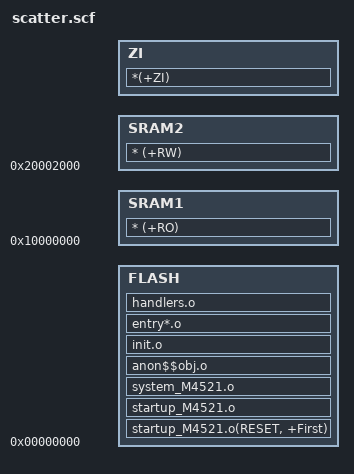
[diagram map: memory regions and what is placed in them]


FLASH 0x00000000
{
    FLASH +0
    {
         startup_M4521.o(RESET, +First)
         startup_M4521.o
         system_M4521.o
         anon$$obj.o
         init.o
         entry*.o
         handlers.o
    }

	SRAM1 0x10000000
    {  
        * (+RO)
    }

    SRAM2 0x20002000
    {
        * (+RW)
    
    }

	ZI +0
	{
		*(+ZI)
	}

}

